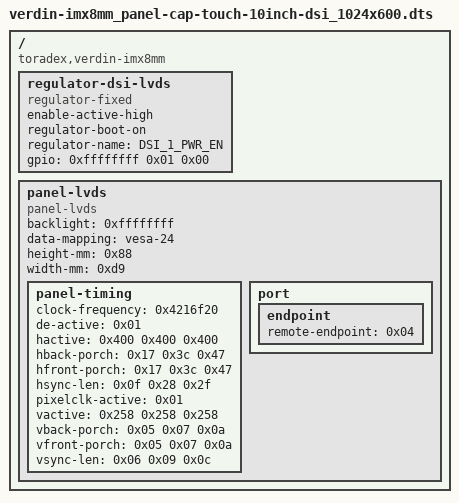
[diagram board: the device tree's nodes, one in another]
/dts-v1/;

/ {
	compatible = "toradex,verdin-imx8mm";

	fragment@0 {
		target-path = "/";

		__overlay__ {

			regulator-dsi-lvds {
				compatible = "regulator-fixed";
				enable-active-high;
				regulator-boot-on;
				regulator-name = "DSI_1_PWR_EN";
				gpio = <0xffffffff 0x01 0x00>;
				phandle = <0x01>;
			};
		};
	};

	fragment@1 {
		target = <0xffffffff>;

		__overlay__ {
			vcc-supply = <0x01>;
			status = "okay";

			ports {
				#address-cells = <0x01>;
				#size-cells = <0x00>;

				port@0 {
					reg = <0x00>;

					endpoint {
						remote-endpoint = <0x02>;
						data-lanes = <0x01 0x02 0x03 0x04>;
						phandle = <0x03>;
					};
				};
			};
		};
	};

	fragment@2 {
		target = <0xffffffff>;

		__overlay__ {
			#address-cells = <0x01>;
			#size-cells = <0x00>;
			status = "okay";

			port@1 {

				endpoint {
					attach-bridge;
					remote-endpoint = <0x03>;
					phandle = <0x02>;
				};
			};
		};
	};

	fragment@3 {
		target-path = "/";

		__overlay__ {

			panel-lvds {
				compatible = "panel-lvds";
				backlight = <0xffffffff>;
				data-mapping = "vesa-24";
				height-mm = <0x88>;
				width-mm = <0xd9>;
				status = "okay";
				phandle = <0x06>;

				panel-timing {
					clock-frequency = <0x4216f20>;
					de-active = <0x01>;
					hactive = <0x400 0x400 0x400>;
					hback-porch = <0x17 0x3c 0x47>;
					hfront-porch = <0x17 0x3c 0x47>;
					hsync-len = <0x0f 0x28 0x2f>;
					pixelclk-active = <0x01>;
					vactive = <0x258 0x258 0x258>;
					vback-porch = <0x05 0x07 0x0a>;
					vfront-porch = <0x05 0x07 0x0a>;
					vsync-len = <0x06 0x09 0x0c>;
				};

				port {

					endpoint {
						remote-endpoint = <0x04>;
						phandle = <0x05>;
					};
				};
			};
		};
	};

	fragment@4 {
		target = <0xffffffff>;

		__overlay__ {
			status = "okay";

			ports {
				#address-cells = <0x01>;
				#size-cells = <0x00>;

				port@2 {
					reg = <0x02>;

					endpoint {
						remote-endpoint = <0x05>;
						phandle = <0x04>;
					};
				};
			};
		};
	};

	fragment@5 {
		target = <0xffffffff>;

		__overlay__ {
			vdd-supply = <0x01>;
			status = "okay";
		};
	};

	fragment@6 {
		target = <0xffffffff>;

		__overlay__ {
			status = "okay";
		};
	};

	fragment@7 {
		target = <0xffffffff>;

		__overlay__ {
			status = "okay";
		};
	};

	fragment@8 {
		target = <0xffffffff>;

		__overlay__ {
			status = "okay";
		};
	};

	fragment@9 {
		target = <0xffffffff>;

		__overlay__ {
			status = "okay";
		};
	};

	__symbols__ {
		reg_dsi_lvds = "/fragment@0/__overlay__/regulator-dsi-lvds";
		dsi84_in = "/fragment@1/__overlay__/ports/port@0/endpoint";
		mipi_dsi_bridge1_out = "/fragment@2/__overlay__/port@1/endpoint";
		panel_lvds = "/fragment@3/__overlay__/panel-lvds";
		panel_in_lvds = "/fragment@3/__overlay__/panel-lvds/port/endpoint";
		lvds_out_panel = "/fragment@4/__overlay__/ports/port@2/endpoint";
	};

	__fixups__ {
		gpio5 = "/fragment@0/__overlay__/regulator-dsi-lvds:gpio:0";
		lvds_ti_sn65dsi84 = "/fragment@1:target:0\0/fragment@4:target:0";
		mipi_dsi = "/fragment@2:target:0";
		backlight = "/fragment@3/__overlay__/panel-lvds:backlight:0\0/fragment@6:target:0";
		atmel_mxt_ts = "/fragment@5:target:0";
		gpu = "/fragment@7:target:0";
		i2c4 = "/fragment@8:target:0";
		lcdif = "/fragment@9:target:0";
	};

	__local_fixups__ {

		fragment@1 {

			__overlay__ {
				vcc-supply = <0x00>;

				ports {

					port@0 {

						endpoint {
							remote-endpoint = <0x00>;
						};
					};
				};
			};
		};

		fragment@2 {

			__overlay__ {

				port@1 {

					endpoint {
						remote-endpoint = <0x00>;
					};
				};
			};
		};

		fragment@3 {

			__overlay__ {

				panel-lvds {

					port {

						endpoint {
							remote-endpoint = <0x00>;
						};
					};
				};
			};
		};

		fragment@4 {

			__overlay__ {

				ports {

					port@2 {

						endpoint {
							remote-endpoint = <0x00>;
						};
					};
				};
			};
		};

		fragment@5 {

			__overlay__ {
				vdd-supply = <0x00>;
			};
		};
	};
};
